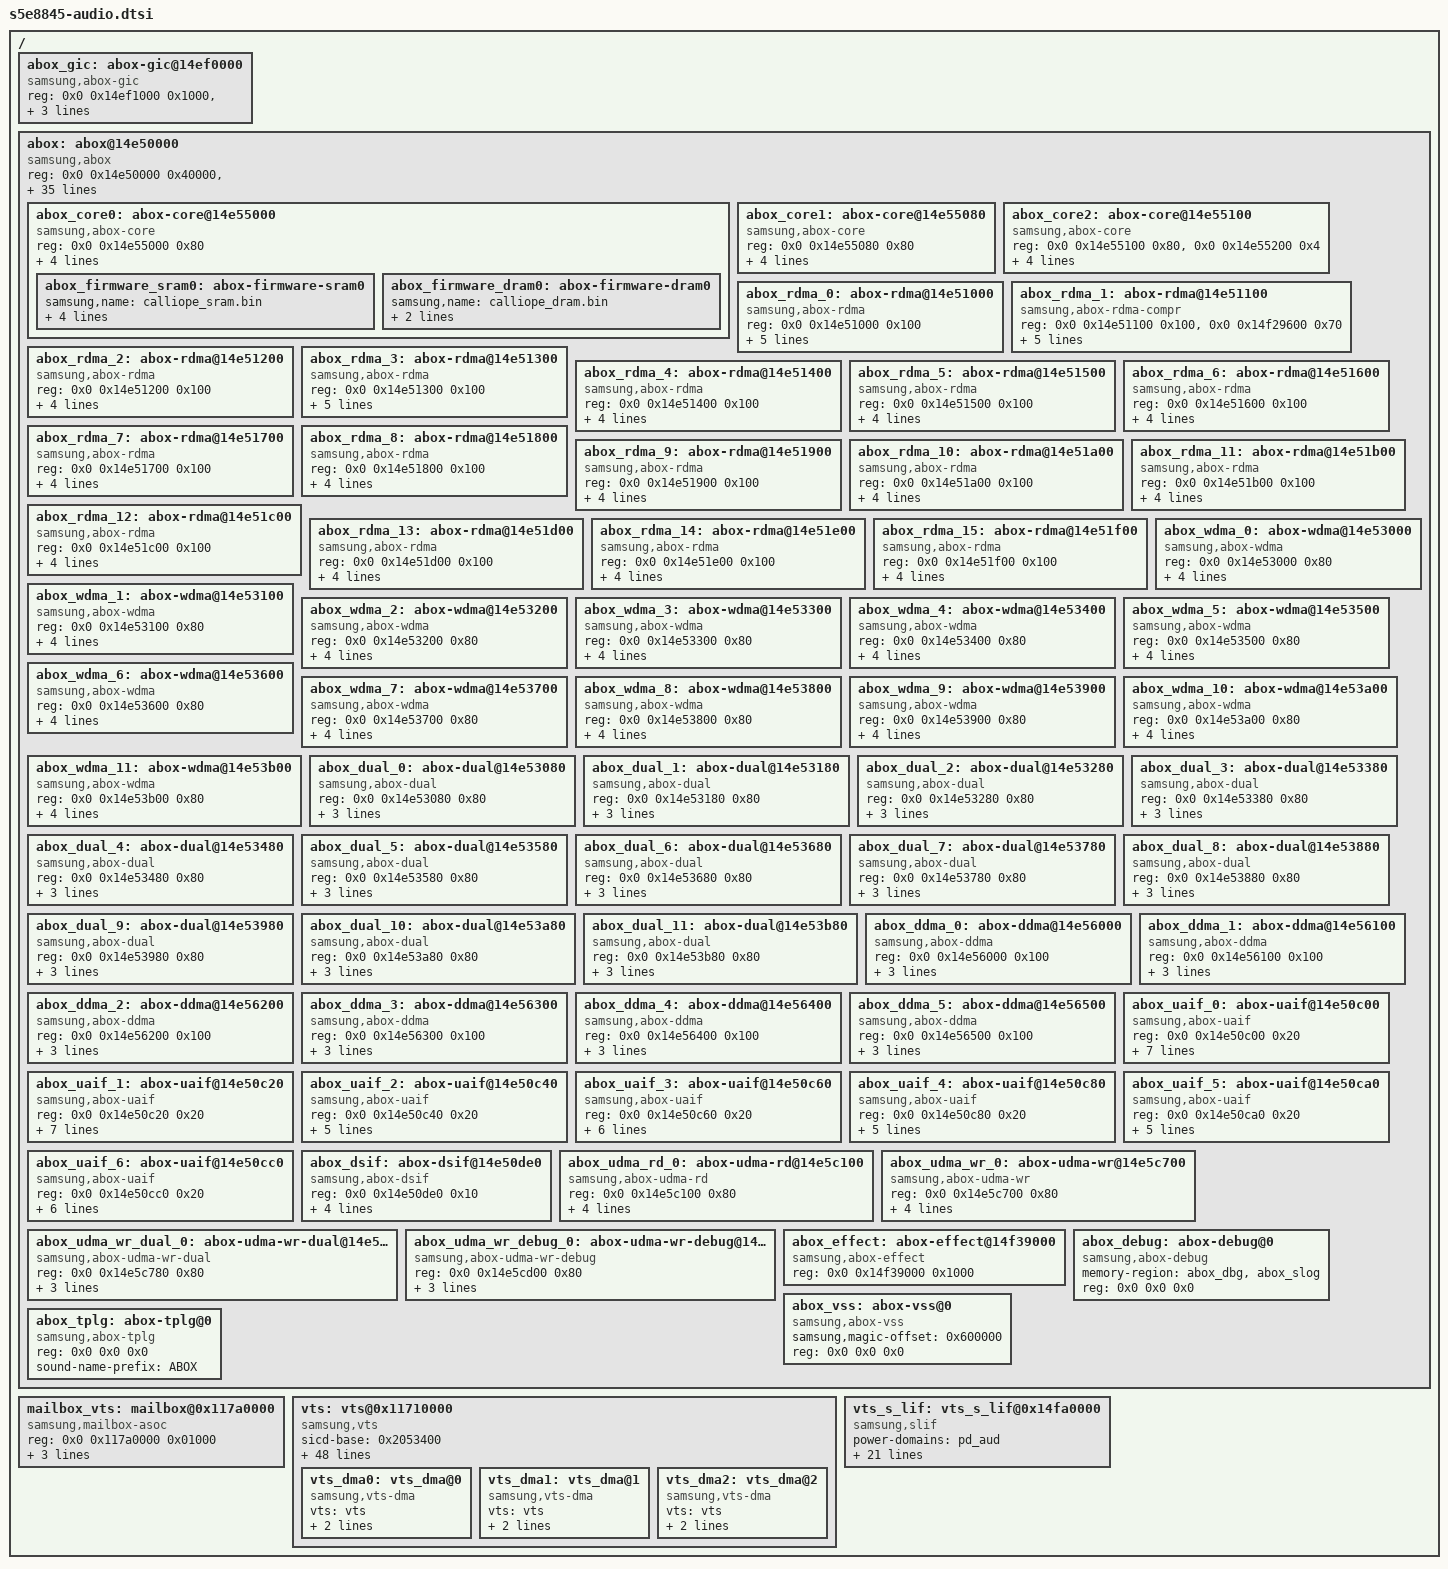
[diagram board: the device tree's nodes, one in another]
/*
 * Samsung's Exynos8845 SoC Audio device tree source
 *
 * Copyright (c) 2023 Samsung Electronics Co., Ltd.
 *		http://www.samsung.com
 *
 * Samsung's Exynos8845 SoC audio devices are listed.
 *
 * This program is free software; you can redistribute it and/or modify
 * it under the terms of the GNU General Public License version 2 as
 * published by the Free Software Foundation.
*/

/ {
	abox_gic: abox-gic@14ef0000 {
		compatible = "samsung,abox-gic";
		reg = <0x0 0x14ef1000 0x1000>, <0x0 0x14ef2000 0x1004>;
		reg-names = "gicd", "gicc";
		interrupts = <GIC_SPI INTREQ__AUD_ABOX_GIC400_MCPU IRQ_TYPE_LEVEL_HIGH>;
	};

	abox: abox@14e50000 {
		compatible = "samsung,abox";
		reg = <0x0 0x14e50000 0x40000>, <0x0 0x14e10000 0x10000>,
			<0x0 0x14f00000 0x85000>, <0x0 0x14ee0000 0x10000>,
			<0x0 0x11A30000 0x1000>, <0x0 0x12900000 0x1000>;
		reg-names = "sfr", "sysreg", "sram", "timer", "mailbox_apm", "cmu_top";
		#address-cells = <2>;
		#size-cells = <1>;
		ranges;
		iommus = <&sysmmu_aud_s0>;
		memory-region = <&abox_rmem>;
		samsung,iommu-group = <&iommu_group_aud>;
		power-domains = <&pd_aud>;
		clocks = <&clock MOUT_CLK_AUD_CPU_PLL>, <&clock DOUT_DIV_CLK_AUD_AUDIF>,
			<&clock DOUT_DIV_CLK_AUD_NOCD>, <&clock DOUT_DIV_CLK_AUD_CNT>,
			<&clock UMUX_CP_PCMC_CLK>, <&clock DOUT_CLK_AUD_PCMC>;
		clock-names = "pll", "audif", "bus", "cnt", "cp_pcmc", "aud_pcmc";
		#sound-dai-cells = <1>;
		sound-name-prefix = "ABOX";
		samsung,quirks = "try to asrc off", "silent reset";
		samsung,ipc-tx-area = <0x1 0x400000 0x18000>;
		samsung,ipc-rx-area = <0x1 0x418000 0x18000>;
		samsung,shm-area = <0x1 0x477000 0x1000>;
		samsung,handshake-area = <0x0 0x292e0 0x20>;
		samsung,abox-bootargs-offset = <0x29500>;
		samsung,abox-slogargs-offset = <0x295f8>;
		samsung,abox-gic = <&abox_gic>;
		samsung,abox-vts = <&vts>;
		samsung,uaif-max-div = <512>;
		samsung,pm-qos-int = <0 0 0 0 0>;
		samsung,pm-qos-aud = <1180000 800000 666000 533000 444000
			400000 333000 267000>;
		samsung,pm-qos-stable-min = <267000>;
		samsung,sys-acp-con = <0x0404 0x10000>;	/* SYSREG: CA32_CON1[16] */
		samsung,pmu-silent-rst = <0x194c 0x00000004>; /* PMU: AUD_OPTION[2] */
		samsung,pmu-pad-ret = <0x1960 0x00000800>;	/* PMU: AUD_OUT[11] */
		samsung,rate-pcmc = <76800000 49152000 73728000>;
		samsung,conf-file-name = "abox_solution.conf", "abox_system.conf";

		abox_core0: abox-core@14e55000 {
			compatible = "samsung,abox-core";
			reg = <0x0 0x14e55000 0x80>;
			reg-names = "gpr";
			samsung,id = <0>;
			samsung,type = "CA32";
			samsung,pmu_power = <0x35c0 0x1>;	/* PMU: AUD_CPU0_CONFIGURATION[0] */
			samsung,sys_standby = <0x0400 0x100000>;	/* SYSREG: CA32_CON0[20] */
			abox_firmware_sram0: abox-firmware-sram0 {
				samsung,name = "calliope_sram.bin";
				samsung,area = <0>; /* 0:SRAM, 1:DRAM */
				samsung,offset = <0x0>;
				samsung,fw-signed;
				samsung,fw-id = <0>;
			};
			abox_firmware_dram0: abox-firmware-dram0 {
				samsung,name = "calliope_dram.bin";
				samsung,area = <1>; /* 0:SRAM, 1:DRAM */
				samsung,offset = <0x0>;
			};
		};

		abox_core1: abox-core@14e55080 {
			compatible = "samsung,abox-core";
			reg = <0x0 0x14e55080 0x80>;
			reg-names = "gpr";
			samsung,id = <1>;
			samsung,type = "CA32";
			samsung,pmu_power = <0x3600 0x1>;	/* PMU: AUD_CPU1_CONFIGURATION[0] */
			samsung,sys_standby = <0x0400 0x200000>;	/* SYSREG: CA32_CON0[21] */
		};

		abox_core2: abox-core@14e55100 {
			compatible = "samsung,abox-core";
			reg = <0x0 0x14e55100 0x80>, <0x0 0x14e55200 0x4>;
			reg-names = "gpr", "status";
			samsung,id = <2>;
			samsung,type = "CA32";
			samsung,pmu_power = <0x3740 0x1>;	/* PMU: AUD_CPU2_CONFIGURATION[0] */
			samsung,sys_standby = <0x0400 0x1400000>;	/* SYSREG: CA32_CON0[22],[24] */
		};

		abox_rdma_0: abox-rdma@14e51000 {
			compatible = "samsung,abox-rdma";
			reg = <0x0 0x14e51000 0x100>;
			reg-names = "sfr";
			samsung,id = <0>;
			samsung,type = "normal";
			samsung,buffer_type = "dma";
			samsung,buffer_bytes = <0x40000>;
			#sound-dai-cells = <1>;
			sound-name-prefix = "ABOX RDMA0";
		};

		abox_rdma_1: abox-rdma@14e51100 {
			compatible = "samsung,abox-rdma-compr";
			reg = <0x0 0x14e51100 0x100>, <0x0 0x14f29600 0x70>;
			reg-names = "sfr", "mailbox";
			memory-region = <&abox_rdma_compr>;
			samsung,id = <1>;
			samsung,type = "compress";
			samsung,buffer_type = "dma";
			#sound-dai-cells = <1>;
			sound-name-prefix = "ABOX ComprTx0";
		};

		abox_rdma_2: abox-rdma@14e51200 {
			compatible = "samsung,abox-rdma";
			reg = <0x0 0x14e51200 0x100>;
			reg-names = "sfr";
			samsung,id = <2>;
			samsung,type = "normal";
			samsung,buffer_type = "ion";
			#sound-dai-cells = <1>;
			sound-name-prefix = "ABOX RDMA2";
		};

		abox_rdma_3: abox-rdma@14e51300 {
			compatible = "samsung,abox-rdma";
			reg = <0x0 0x14e51300 0x100>;
			reg-names = "sfr";
			samsung,id = <3>;
			samsung,type = "normal";
			samsung,buffer_type = "dma";
			samsung,asrc-id = <7>;
			#sound-dai-cells = <1>;
			sound-name-prefix = "ABOX RDMA3";
		};

		abox_rdma_4: abox-rdma@14e51400 {
			compatible = "samsung,abox-rdma";
			reg = <0x0 0x14e51400 0x100>;
			reg-names = "sfr";
			samsung,id = <4>;
			samsung,type = "normal";
			samsung,buffer_type = "dma";
			#sound-dai-cells = <1>;
			sound-name-prefix = "ABOX RDMA4";
		};

		abox_rdma_5: abox-rdma@14e51500 {
			compatible = "samsung,abox-rdma";
			reg = <0x0 0x14e51500 0x100>;
			reg-names = "sfr";
			samsung,id = <5>;
			samsung,type = "normal";
			samsung,buffer_type = "dma";
			#sound-dai-cells = <1>;
			sound-name-prefix = "ABOX RDMA5";
		};

		abox_rdma_6: abox-rdma@14e51600 {
			compatible = "samsung,abox-rdma";
			reg = <0x0 0x14e51600 0x100>;
			reg-names = "sfr";
			samsung,id = <6>;
			samsung,type = "normal";
			samsung,buffer_type = "dma";
			#sound-dai-cells = <1>;
			sound-name-prefix = "ABOX RDMA6";
		};

		abox_rdma_7: abox-rdma@14e51700 {
			compatible = "samsung,abox-rdma";
			reg = <0x0 0x14e51700 0x100>;
			reg-names = "sfr";
			samsung,id = <7>;
			samsung,type = "normal";
			samsung,buffer_type = "dma";
			#sound-dai-cells = <1>;
			sound-name-prefix = "ABOX RDMA7";
		};

		abox_rdma_8: abox-rdma@14e51800 {
			compatible = "samsung,abox-rdma";
			reg = <0x0 0x14e51800 0x100>;
			reg-names = "sfr";
			samsung,id = <8>;
			samsung,type = "normal";
			samsung,buffer_type = "dma";
			#sound-dai-cells = <1>;
			sound-name-prefix = "ABOX RDMA8";
		};

		abox_rdma_9: abox-rdma@14e51900 {
			compatible = "samsung,abox-rdma";
			reg = <0x0 0x14e51900 0x100>;
			reg-names = "sfr";
			samsung,id = <9>;
			samsung,type = "normal";
			samsung,buffer_type = "dma";
			#sound-dai-cells = <1>;
			sound-name-prefix = "ABOX RDMA9";
		};

		abox_rdma_10: abox-rdma@14e51a00 {
			compatible = "samsung,abox-rdma";
			reg = <0x0 0x14e51a00 0x100>;
			reg-names = "sfr";
			samsung,id = <10>;
			samsung,type = "normal";
			samsung,buffer_type = "dma";
			#sound-dai-cells = <1>;
			sound-name-prefix = "ABOX RDMA10";
		};

		abox_rdma_11: abox-rdma@14e51b00 {
			compatible = "samsung,abox-rdma";
			reg = <0x0 0x14e51b00 0x100>;
			reg-names = "sfr";
			samsung,id = <11>;
			samsung,type = "normal";
			samsung,buffer_type = "dma";
			#sound-dai-cells = <1>;
			sound-name-prefix = "ABOX RDMA11";
		};

		abox_rdma_12: abox-rdma@14e51c00 {
			compatible = "samsung,abox-rdma";
			reg = <0x0 0x14e51c00 0x100>;
			reg-names = "sfr";
			samsung,id = <12>;
			samsung,type = "normal";
			samsung,buffer_type = "dma";
			#sound-dai-cells = <1>;
			sound-name-prefix = "ABOX RDMA12";
		};

		abox_rdma_13: abox-rdma@14e51d00 {
			compatible = "samsung,abox-rdma";
			reg = <0x0 0x14e51d00 0x100>;
			reg-names = "sfr";
			samsung,id = <13>;
			samsung,type = "normal";
			samsung,buffer_type = "dma";
			#sound-dai-cells = <1>;
			sound-name-prefix = "ABOX RDMA13";
		};

		abox_rdma_14: abox-rdma@14e51e00 {
			compatible = "samsung,abox-rdma";
			reg = <0x0 0x14e51e00 0x100>;
			reg-names = "sfr";
			samsung,id = <14>;
			samsung,type = "normal";
			samsung,buffer_type = "dma";
			#sound-dai-cells = <1>;
			sound-name-prefix = "ABOX RDMA14";
		};

		abox_rdma_15: abox-rdma@14e51f00 {
			compatible = "samsung,abox-rdma";
			reg = <0x0 0x14e51f00 0x100>;
			reg-names = "sfr";
			samsung,id = <15>;
			samsung,type = "normal";
			samsung,buffer_type = "dma";
			#sound-dai-cells = <1>;
			sound-name-prefix = "ABOX RDMA15";
		};

		abox_wdma_0: abox-wdma@14e53000 {
			compatible = "samsung,abox-wdma";
			reg = <0x0 0x14e53000 0x80>;
			reg-names = "sfr";
			samsung,id = <0>;
			samsung,type = "normal";
			samsung,buffer_type = "dma";
			#sound-dai-cells = <1>;
			sound-name-prefix = "ABOX WDMA0";
		};

		abox_wdma_1: abox-wdma@14e53100 {
			compatible = "samsung,abox-wdma";
			reg = <0x0 0x14e53100 0x80>;
			reg-names = "sfr";
			samsung,id = <1>;
			samsung,type = "normal";
			samsung,buffer_type = "ion";
			#sound-dai-cells = <1>;
			sound-name-prefix = "ABOX WDMA1";
		};

		abox_wdma_2: abox-wdma@14e53200 {
			compatible = "samsung,abox-wdma";
			reg = <0x0 0x14e53200 0x80>;
			reg-names = "sfr";
			samsung,id = <2>;
			samsung,type = "normal";
			samsung,buffer_type = "dma";
			#sound-dai-cells = <1>;
			sound-name-prefix = "ABOX WDMA2";
		};

		abox_wdma_3: abox-wdma@14e53300 {
			compatible = "samsung,abox-wdma";
			reg = <0x0 0x14e53300 0x80>;
			reg-names = "sfr";
			samsung,id = <3>;
			samsung,type = "normal";
			samsung,buffer_type = "dma";
			#sound-dai-cells = <1>;
			sound-name-prefix = "ABOX WDMA3";
		};

		abox_wdma_4: abox-wdma@14e53400 {
			compatible = "samsung,abox-wdma";
			reg = <0x0 0x14e53400 0x80>;
			reg-names = "sfr";
			samsung,id = <4>;
			samsung,type = "normal";
			samsung,buffer_type = "dma";
			#sound-dai-cells = <1>;
			sound-name-prefix = "ABOX WDMA4";
		};

		abox_wdma_5: abox-wdma@14e53500 {
			compatible = "samsung,abox-wdma";
			reg = <0x0 0x14e53500 0x80>;
			reg-names = "sfr";
			samsung,id = <5>;
			samsung,type = "normal";
			samsung,buffer_type = "dma";
			#sound-dai-cells = <1>;
			sound-name-prefix = "ABOX WDMA5";
		};

		abox_wdma_6: abox-wdma@14e53600 {
			compatible = "samsung,abox-wdma";
			reg = <0x0 0x14e53600 0x80>;
			reg-names = "sfr";
			samsung,id = <6>;
			samsung,type = "normal";
			samsung,buffer_type = "ion";
			#sound-dai-cells = <1>;
			sound-name-prefix = "ABOX WDMA6";
		};

		abox_wdma_7: abox-wdma@14e53700 {
			compatible = "samsung,abox-wdma";
			reg = <0x0 0x14e53700 0x80>;
			reg-names = "sfr";
			samsung,id = <7>;
			samsung,type = "normal";
			samsung,buffer_type = "dma";
			#sound-dai-cells = <1>;
			sound-name-prefix = "ABOX WDMA7";
		};

		abox_wdma_8: abox-wdma@14e53800 {
			compatible = "samsung,abox-wdma";
			reg = <0x0 0x14e53800 0x80>;
			reg-names = "sfr";
			samsung,id = <8>;
			samsung,type = "normal";
			samsung,buffer_type = "dma";
			#sound-dai-cells = <1>;
			sound-name-prefix = "ABOX WDMA8";
		};

		abox_wdma_9: abox-wdma@14e53900 {
			compatible = "samsung,abox-wdma";
			reg = <0x0 0x14e53900 0x80>;
			reg-names = "sfr";
			samsung,id = <9>;
			samsung,type = "normal";
			samsung,buffer_type = "dma";
			#sound-dai-cells = <1>;
			sound-name-prefix = "ABOX WDMA9";
		};

		abox_wdma_10: abox-wdma@14e53a00 {
			compatible = "samsung,abox-wdma";
			reg = <0x0 0x14e53a00 0x80>;
			reg-names = "sfr";
			samsung,id = <10>;
			samsung,type = "normal";
			samsung,buffer_type = "dma";
			#sound-dai-cells = <1>;
			sound-name-prefix = "ABOX WDMA10";
		};

		abox_wdma_11: abox-wdma@14e53b00 {
			compatible = "samsung,abox-wdma";
			reg = <0x0 0x14e53b00 0x80>;
			reg-names = "sfr";
			samsung,id = <11>;
			samsung,type = "normal";
			samsung,buffer_type = "dma";
			#sound-dai-cells = <1>;
			sound-name-prefix = "ABOX WDMA11";
		};

		abox_dual_0: abox-dual@14e53080 {
			compatible = "samsung,abox-dual";
			reg = <0x0 0x14e53080 0x80>;
			reg-names = "sfr";
			samsung,id = <0>;
			samsung,buffer_type = "dma";
			#sound-dai-cells = <0>;
			sound-name-prefix = "ABOX WDMA0 DUAL";
		};

		abox_dual_1: abox-dual@14e53180 {
			compatible = "samsung,abox-dual";
			reg = <0x0 0x14e53180 0x80>;
			reg-names = "sfr";
			samsung,id = <1>;
			samsung,buffer_type = "dma";
			#sound-dai-cells = <0>;
			sound-name-prefix = "ABOX WDMA1 DUAL";
		};

		abox_dual_2: abox-dual@14e53280 {
			compatible = "samsung,abox-dual";
			reg = <0x0 0x14e53280 0x80>;
			reg-names = "sfr";
			samsung,id = <2>;
			samsung,buffer_type = "dma";
			#sound-dai-cells = <0>;
			sound-name-prefix = "ABOX WDMA2 DUAL";
		};

		abox_dual_3: abox-dual@14e53380 {
			compatible = "samsung,abox-dual";
			reg = <0x0 0x14e53380 0x80>;
			reg-names = "sfr";
			samsung,id = <3>;
			samsung,buffer_type = "dma";
			#sound-dai-cells = <0>;
			sound-name-prefix = "ABOX WDMA3 DUAL";
		};

		abox_dual_4: abox-dual@14e53480 {
			compatible = "samsung,abox-dual";
			reg = <0x0 0x14e53480 0x80>;
			reg-names = "sfr";
			samsung,id = <4>;
			samsung,buffer_type = "dma";
			#sound-dai-cells = <0>;
			sound-name-prefix = "ABOX WDMA4 DUAL";
		};

		abox_dual_5: abox-dual@14e53580 {
			compatible = "samsung,abox-dual";
			reg = <0x0 0x14e53580 0x80>;
			reg-names = "sfr";
			samsung,id = <5>;
			samsung,buffer_type = "dma";
			#sound-dai-cells = <0>;
			sound-name-prefix = "ABOX WDMA5 DUAL";
		};

		abox_dual_6: abox-dual@14e53680 {
			compatible = "samsung,abox-dual";
			reg = <0x0 0x14e53680 0x80>;
			reg-names = "sfr";
			samsung,id = <6>;
			samsung,buffer_type = "dma";
			#sound-dai-cells = <0>;
			sound-name-prefix = "ABOX WDMA6 DUAL";
		};

		abox_dual_7: abox-dual@14e53780 {
			compatible = "samsung,abox-dual";
			reg = <0x0 0x14e53780 0x80>;
			reg-names = "sfr";
			samsung,id = <7>;
			samsung,buffer_type = "dma";
			#sound-dai-cells = <0>;
			sound-name-prefix = "ABOX WDMA7 DUAL";
		};

		abox_dual_8: abox-dual@14e53880 {
			compatible = "samsung,abox-dual";
			reg = <0x0 0x14e53880 0x80>;
			reg-names = "sfr";
			samsung,id = <8>;
			samsung,buffer_type = "dma";
			#sound-dai-cells = <0>;
			sound-name-prefix = "ABOX WDMA8 DUAL";
		};

		abox_dual_9: abox-dual@14e53980 {
			compatible = "samsung,abox-dual";
			reg = <0x0 0x14e53980 0x80>;
			reg-names = "sfr";
			samsung,id = <9>;
			samsung,buffer_type = "dma";
			#sound-dai-cells = <0>;
			sound-name-prefix = "ABOX WDMA9 DUAL";
		};

		abox_dual_10: abox-dual@14e53a80 {
			compatible = "samsung,abox-dual";
			reg = <0x0 0x14e53a80 0x80>;
			reg-names = "sfr";
			samsung,id = <10>;
			samsung,buffer_type = "dma";
			#sound-dai-cells = <0>;
			sound-name-prefix = "ABOX WDMA10 DUAL";
		};

		abox_dual_11: abox-dual@14e53b80 {
			compatible = "samsung,abox-dual";
			reg = <0x0 0x14e53b80 0x80>;
			reg-names = "sfr";
			samsung,id = <11>;
			samsung,buffer_type = "dma";
			#sound-dai-cells = <0>;
			sound-name-prefix = "ABOX WDMA11 DUAL";
		};

		abox_ddma_0: abox-ddma@14e56000 {
			compatible = "samsung,abox-ddma";
			reg = <0x0 0x14e56000 0x100>;
			reg-names = "sfr";
			samsung,id = <0>;
			samsung,buffer_type = "dma";
			#sound-dai-cells = <0>;
			sound-name-prefix = "ABOX DBG0";
		};

		abox_ddma_1: abox-ddma@14e56100 {
			compatible = "samsung,abox-ddma";
			reg = <0x0 0x14e56100 0x100>;
			reg-names = "sfr";
			samsung,id = <1>;
			samsung,buffer_type = "dma";
			#sound-dai-cells = <0>;
			sound-name-prefix = "ABOX DBG1";
		};

		abox_ddma_2: abox-ddma@14e56200 {
			compatible = "samsung,abox-ddma";
			reg = <0x0 0x14e56200 0x100>;
			reg-names = "sfr";
			samsung,id = <2>;
			samsung,buffer_type = "dma";
			#sound-dai-cells = <0>;
			sound-name-prefix = "ABOX DBG2";
		};

		abox_ddma_3: abox-ddma@14e56300 {
			compatible = "samsung,abox-ddma";
			reg = <0x0 0x14e56300 0x100>;
			reg-names = "sfr";
			samsung,id = <3>;
			samsung,buffer_type = "dma";
			#sound-dai-cells = <0>;
			sound-name-prefix = "ABOX DBG3";
		};

		abox_ddma_4: abox-ddma@14e56400 {
			compatible = "samsung,abox-ddma";
			reg = <0x0 0x14e56400 0x100>;
			reg-names = "sfr";
			samsung,id = <4>;
			samsung,buffer_type = "dma";
			#sound-dai-cells = <0>;
			sound-name-prefix = "ABOX DBG4";
		};

		abox_ddma_5: abox-ddma@14e56500 {
			compatible = "samsung,abox-ddma";
			reg = <0x0 0x14e56500 0x100>;
			reg-names = "sfr";
			samsung,id = <5>;
			samsung,buffer_type = "dma";
			#sound-dai-cells = <0>;
			sound-name-prefix = "ABOX DBG5";
		};

		abox_uaif_0: abox-uaif@14e50c00 {
			compatible = "samsung,abox-uaif";
			reg = <0x0 0x14e50c00 0x20>;
			reg-names = "sfr";
			samsung,id = <0>;
			clocks = <&clock DOUT_DIV_CLK_AUD_UAIF0>, <&clock GATE_ABOX_QCH_BCLK0>,
				<&clock MOUT_CLK_AUD_UAIF0>;
			clock-names = "bclk", "bclk_gate", "mux";
			pinctrl-names = "active", "idle";
			pinctrl-0 = <&aud_i2s0_bus &aud_codec_mclk>;
			pinctrl-1 = <&aud_i2s0_idle &aud_codec_mclk_idle>;
			#sound-dai-cells = <0>;
			sound-name-prefix = "ABOX UAIF0";
		};

		abox_uaif_1: abox-uaif@14e50c20 {
			compatible = "samsung,abox-uaif";
			reg = <0x0 0x14e50c20 0x20>;
			reg-names = "sfr";
			samsung,id = <1>;
			clocks = <&clock DOUT_DIV_CLK_AUD_UAIF1>, <&clock GATE_ABOX_QCH_BCLK1>,
				<&clock MOUT_CLK_AUD_UAIF1>;
			clock-names = "bclk", "bclk_gate", "mux";
			pinctrl-names = "active", "idle";
			pinctrl-0 = <&aud_i2s1_bus>;
			pinctrl-1 = <&aud_i2s1_idle>;
			#sound-dai-cells = <0>;
			sound-name-prefix = "ABOX UAIF1";
		};

		abox_uaif_2: abox-uaif@14e50c40 {
			compatible = "samsung,abox-uaif";
			reg = <0x0 0x14e50c40 0x20>;
			reg-names = "sfr";
			samsung,id = <2>;
			clocks = <&clock DOUT_DIV_CLK_AUD_UAIF2>, <&clock GATE_ABOX_QCH_BCLK2>,
				<&clock MOUT_CLK_AUD_UAIF2>;
			clock-names = "bclk", "bclk_gate", "mux";
			#sound-dai-cells = <0>;
			sound-name-prefix = "ABOX UAIF2";
		};

		abox_uaif_3: abox-uaif@14e50c60 {
			compatible = "samsung,abox-uaif";
			reg = <0x0 0x14e50c60 0x20>;
			reg-names = "sfr";
			samsung,id = <3>;
			samsung,quirks = "chub gpio";
			clocks = <&clock DOUT_DIV_CLK_AUD_UAIF3>, <&clock GATE_ABOX_QCH_BCLK3>,
				<&clock MOUT_CLK_AUD_UAIF3>;
			clock-names = "bclk", "bclk_gate", "mux";
			#sound-dai-cells = <0>;
			sound-name-prefix = "ABOX UAIF3";
		};

		abox_uaif_4: abox-uaif@14e50c80 {
			compatible = "samsung,abox-uaif";
			reg = <0x0 0x14e50c80 0x20>;
			reg-names = "sfr";
			samsung,id = <4>;
			clocks = <&clock DOUT_DIV_CLK_AUD_UAIF4>, <&clock GATE_ABOX_QCH_BCLK4>,
				<&clock MOUT_CLK_AUD_UAIF4>;
			clock-names = "bclk", "bclk_gate", "mux";
			#sound-dai-cells = <0>;
			sound-name-prefix = "ABOX UAIF4";
		};

		abox_uaif_5: abox-uaif@14e50ca0 {
			compatible = "samsung,abox-uaif";
			reg = <0x0 0x14e50ca0 0x20>;
			reg-names = "sfr";
			samsung,id = <5>;
			clocks = <&clock DOUT_DIV_CLK_AUD_UAIF5>, <&clock GATE_ABOX_QCH_BCLK5>,
				<&clock MOUT_CLK_AUD_UAIF5>;
			clock-names = "bclk", "bclk_gate", "mux";
			#sound-dai-cells = <0>;
			sound-name-prefix = "ABOX UAIF5";
		};

		abox_uaif_6: abox-uaif@14e50cc0 {
			compatible = "samsung,abox-uaif";
			reg = <0x0 0x14e50cc0 0x20>;
			reg-names = "sfr";
			samsung,id = <6>;
			clocks = <&clock DOUT_DIV_CLK_AUD_UAIF6>, <&clock GATE_ABOX_QCH_BCLK6>,
				<&clock MOUT_CLK_AUD_UAIF6>;
			clock-names = "bclk", "bclk_gate", "mux";
			#sound-dai-cells = <0>;
			sound-name-prefix = "ABOX UAIF6";
			samsung,real-i2s; /*SW work Around: BCLK inversion, negative edge capture*/
		};

		abox_dsif: abox-dsif@14e50de0 {
			compatible = "samsung,abox-dsif";
			reg = <0x0 0x14e50de0 0x10>;
			reg-names = "sfr";
			samsung,id = <7>;
			clocks = <&clock DOUT_DIV_CLK_AUD_DSIF>, <&clock GATE_ABOX_QCH_BCLK_DSIF>;
			clock-names = "bclk", "bclk_gate";
			/* DSIF and UAIF1 shares GPIO
			 * pinctrl-names = "default", "sleep";
			 * pinctrl-0 = <&aud_dsd_bus>;
			 * pinctrl-1 = <&aud_dsd_idle>;
			 */
			#sound-dai-cells = <0>;
			sound-name-prefix = "ABOX DSIF";
		};

		abox_udma_rd_0: abox-udma-rd@14e5c100 {
			compatible = "samsung,abox-udma-rd";
			reg = <0x0 0x14e5c100 0x80>;
			reg-names = "sfr";
			samsung,id = <0>;
			samsung,buffer_type = "ram";
			samsung,buffer-address = <0x3 0x14f36000 0x3000>;
			#sound-dai-cells = <0>;
			sound-name-prefix = "ABOX UDMA RD0";
		};

		abox_udma_wr_0: abox-udma-wr@14e5c700 {
			compatible = "samsung,abox-udma-wr";
			reg = <0x0 0x14e5c700 0x80>;
			reg-names = "sfr";
			samsung,id = <0>;
			samsung,buffer_type = "ram";
			samsung,buffer-address = <0x3 0x14f2a000 0xc000>;
			#sound-dai-cells = <0>;
			sound-name-prefix = "ABOX UDMA WR0";
		};

		abox_udma_wr_dual_0: abox-udma-wr-dual@14e5c780 {
			compatible = "samsung,abox-udma-wr-dual";
			reg = <0x0 0x14e5c780 0x80>;
			reg-names = "sfr";
			samsung,id = <0>;
			samsung,buffer_type = "dma";
			#sound-dai-cells = <0>;
			sound-name-prefix = "ABOX UDMA WR0 DUAL";
		};

		abox_udma_wr_debug_0: abox-udma-wr-debug@14e5cd00 {
			compatible = "samsung,abox-udma-wr-debug";
			reg = <0x0 0x14e5cd00 0x80>;
			reg-names = "sfr";
			samsung,id = <0>;
			samsung,buffer_type = "dma";
			#sound-dai-cells = <0>;
			sound-name-prefix = "ABOX UDMA DBG0";
		};

		abox_effect: abox-effect@14f39000 {
			compatible = "samsung,abox-effect";
			reg = <0x0 0x14f39000 0x1000>; /* sram + 0x39000 */
			reg-names = "reg";
		};

		abox_debug: abox-debug@0 {
			compatible = "samsung,abox-debug";
			memory-region = <&abox_dbg &abox_slog>;
			reg = <0x0 0x0 0x0>;
		};

		abox_vss: abox-vss@0 {
			compatible = "samsung,abox-vss";
			samsung,magic-offset = <0x600000>;
			reg = <0x0 0x0 0x0>;
		};

		abox_tplg: abox-tplg@0 {
			compatible = "samsung,abox-tplg";
			reg = <0x0 0x0 0x0>;
			sound-name-prefix = "ABOX";
		};
	};

	mailbox_vts: mailbox@0x117a0000 {
		compatible = "samsung,mailbox-asoc";
		reg = <0x0 0x117a0000 0x01000>;
		reg-names = "sfr";
		interrupts = <GIC_SPI INTREQ__MAILBOX_AP_VTS IRQ_TYPE_LEVEL_HIGH>;
		interrupt-controller;
		#interrupt-cells = <1>;
	};

	vts: vts@0x11710000 {
		compatible = "samsung,vts";
		sicd-base = <0x2053400>;
		sicd-size = <0x400>;
		reg = <0x0 0x11710000 0x1020>, <0x0 0x11640000 0x10000>,
			<0x0 0x11770000 0x8>, <0x0 0x117d0000 0x8>,
			<0x0 0x11300000 0xc0000>, <0x0 0x117f0000 0x50>,
			<0x0 0x11750000 0x8>, <0x0 0x11720000 0x8>;
		reg-names = "sfr", "baaw",
			"dmic", "dmic1",
			"sram", "gpr",
			"dmic_ahb0", "timer0";
		#address-cells = <2>;
		#size-cells = <1>;
		ranges;

		pinctrl-names = "dmic0_default",
			"dmic1_default",
			"dmic2_default",
			"amic0_default",
			"amic1_default",
			"amic2_default",
			"dmic0_idle",
			"dmic1_idle",
			"dmic2_idle",
			"default";
		pinctrl-0 = <&dmic_bus_clk0 &dmic_pdm0_bus>;
		pinctrl-1 = <&dmic_bus_clk2 &dmic_pdm2_bus>;
		pinctrl-2 = <&dmic_bus_clk2 &dmic_pdm2_bus>;
		pinctrl-3 = <&dmic_bus_clk0 &amic_pdm0_bus>;
		pinctrl-4 = <&dmic_bus_clk1 &amic_pdm1_bus>;
		pinctrl-5 = <&dmic_bus_clk2 &amic_pdm2_bus>;
		pinctrl-6 = <&dmic_bus_clk0_idle &dmic_pdm0_idle>;
		pinctrl-7 = <&dmic_bus_clk2_idle &dmic_pdm2_idle>;
		pinctrl-8 = <&dmic_bus_clk2_idle &dmic_pdm2_idle>;
		pinctrl-9 = <>;

		power-domains = <&pd_vts>;

		clocks = <&clock DOUT_CLKALIVE_CHUBVTS_NOC>,    /* 0 */
			<&clock DOUT_DIV_CLK_VTS_NOC>,		        /* 1 */
			<&clock DOUT_DIV_CLK_VTS_DMIC_IF>,	        /* 2 */
			<&clock DOUT_DIV_CLK_VTS_DMIC_IF_DIV2>,	    /* 3 */
			<&clock MOUT_MUX_VTS_DMIC_AUD>,             /* 4 */
			<&clock DOUT_DIV_VTS_DMIC_AUD>,	            /* 5 */
			<&clock MOUT_MUX_CLKCMU_VTS_NOC_USER>,      /* 6 */
			<&clock MOUT_MUX_CLKCMU_VTS_RCO_USER>,	    /* 7 */
			<&clock MOUT_MUX_CLKCMU_AUD_DMIC_BUS_USER>;	/* 8 */
		clock-names = "clk_src0",
			"clk_src1",
			"clk_src2",
			"clk_src3",
			"clk_src4",
			"clk_src5",
			"clk_src6",
			"clk_src7",
			"clk_src8";
		clk-name-list = "DOUT_CLKALIVE_CHUBVTS_NOC",	/* 0 */
			"DOUT_DIV_CLK_VTS_NOC",			            /* 1 */
			"DOUT_DIV_CLK_VTS_DMIC_IF",		            /* 2 */
			"DOUT_DIV_CLK_VTS_DMIC_IF_DIV2",            /* 3 */
			"MOUT_MUX_VTS_DMIC_AUD",		            /* 4 */
			"DOUT_DIV_VTS_DMIC_AUD",		            /* 5 */
			"MOUT_MUX_CLKCMU_VTS_NOC_USER",             /* 6 */
			"MOUT_MUX_CLKCMU_VTS_RCO_USER",		        /* 7 */
			"MOUT_MUX_CLKCMU_AUD_DMIC_BUS_USER";        /* 8 */
		vts-init-clk = <0 400000000>;
		vts-alive-clk = <6 393216000 7 24576000>;
		vts-sys-clk = <1 196608000>;
		vts-tri-clk = <4 24576000 5 12288000
					2 1536000 3 768000>;
		vts-aud-clk = <4 73728000 5 12288000
					2 6144000 3 3072000>;

		mailbox = <&mailbox_vts>;
		#sound-dai-cells = <1>;
		sound-name-prefix = "VTS";
		interrupt-parent = <&mailbox_vts>;
		interrupts = <0>, <1>, <2>, <3>, <4>, <5>, <6>, <7>, <10>, <11>, <15>;
		interrupt-names = "error", "boot_completed", "ipc_received", "voice_triggered",
				"trigger_period_elapsed", "record_period_elapsed",
				"debuglog_bufzero", "internal_rec_elapsed", "vts_status",
				"slif_dump", "cp_wakeup";
		samsung,imgloader-vts-support;
		samsung,fw-id = <0>;
		vts_dma0: vts_dma@0 {
			compatible = "samsung,vts-dma";
			vts = <&vts>;
			id = <0>;
			type = "vts-trigger";
		};

		vts_dma1: vts_dma@1 {
			compatible = "samsung,vts-dma";
			vts = <&vts>;
			id = <1>;
			type = "vts-record";
		};
		vts_dma2: vts_dma@2 {
			compatible = "samsung,vts-dma";
			vts = <&vts>;
			id = <2>;
			type = "vts-internal";
		};
	};

	vts_s_lif: vts_s_lif@0x14fa0000 {
		compatible = "samsung,slif";
		status = "okay";
		power-domains = <&pd_aud>;
		samsung,slif-vts = <&vts>;
		id = <0>;
		reg = <0x0 0x14ed0000 0x400>, <0x0 0x14fe0000 0x20>,
			<0x0 0x14ff0000 0x20>;
		reg-names = "sfr", "dmic_aud0", "dmic_aud1";
		clocks = <&clock MOUT_MUX_CLKCMU_AUD_DMIC_BUS_USER>,  /* 0 */
			<&clock MOUT_MUX_VTS_DMIC_AUD>,                   /* 1 */
			<&clock DOUT_DIV_VTS_DMIC_AUD>,	                  /* 2 */
			<&clock DOUT_CLK_AUD_SERIAL_LIF>,	              /* 3 */
			<&clock DOUT_DIV_CLK_VTS_DMIC_IF>,                /* 4 */
			<&clock DOUT_DIV_CLK_VTS_DMIC_IF_DIV2>;           /* 5 */
		clock-names = "clk_src0",
			"clk_src1",
			"clk_src2",
			"clk_src3",
			"clk_src4",
			"clk_src5";
		clk-name-list = "MOUT_MUX_CLKCMU_AUD_DMIC_BUS_USER",  /* 0 */
			"MOUT_MUX_VTS_DMIC_AUD",		                  /* 1 */
			"DOUT_DIV_VTS_DMIC_AUD",		                  /* 2 */
			"DOUT_CLK_AUD_SERIAL_LIF",		                  /* 3 */
			"DOUT_DIV_CLK_VTS_DMIC_IF",		                  /* 4 */
			"DOUT_DIV_CLK_VTS_DMIC_IF_DIV2";	              /* 5 */
		slif-aud-clk = <0 73728000 1 73728000 2 12288000 4 6144000 5 3072000>;
		slif-bclk = <3 4608000>;

		#sound-dai-cells = <1>;
	};

};
